# moondancer register map
Vendor: luna-soc
TODO device.description
Registers are 8-bit, read-write, reset 0x0 unless marked. A register's access mark holds for its fields unless they carry their own. Offsets are from the block's base; lines under a group give offsets from that group; [hi:lo] are bit positions; {n}, {i} and the like mark numbered series; 'fields as' and 'values as' point back to an identical list; <NAME> marks a mode.

## Memory map
0xF0000000 leds size 0x6
0xF0000100 gpio0 size 0x6
0xF0000200 gpio1 size 0x6
0xF0000300 uart0 size 0x14
0xF0000400 uart1 size 0x14
0xF0000500 timer0 size 0x12
0xF0000600 timer1 size 0x12
0xF0000700 spi0 size 0x10
0xF0000800 usb0 size 0xA
0xF0000900 usb0_ep_control size 0x12
0xF0000A00 usb0_ep_in size 0x12
0xF0000B00 usb0_ep_out size 0x22
0xF0000C00 usb1 size 0xA
0xF0000D00 usb1_ep_control size 0x12
0xF0000E00 usb1_ep_in size 0x12
0xF0000F00 usb1_ep_out size 0x22
0xF0001000 usb2 size 0xA
0xF0001100 usb2_ep_control size 0x12
0xF0001200 usb2_ep_in size 0x12
0xF0001300 usb2_ep_out size 0x22
0xF0001400 advertiser size 0x1
0xF0001500 info size 0x2
0xF0001600 user0 size 0x4

## Interrupts
0 timer0
1 timer1
2 usb0
3 usb0_ep_control
4 usb0_ep_in
5 usb0_ep_out
6 usb1
7 usb1_ep_control
8 usb1_ep_in
9 usb1_ep_out
10 usb2
11 usb2_ep_control
12 usb2_ep_in
13 usb2_ep_out

## leds
Base 0xF0000000
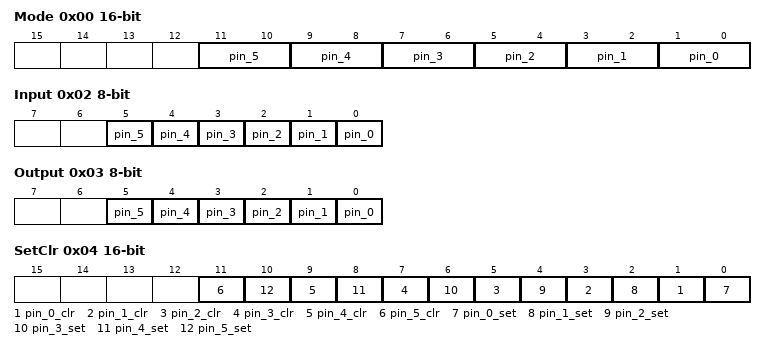
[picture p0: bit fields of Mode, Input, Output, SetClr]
0x00 Mode 16-bit — Mode register. This :class:`csr.Register` contains an array of ``pin_count`` read/write fields. Each field is 2-bit wide and its possible values are defined by the :class:`PinMode` enumeration. If ``pin_count`` is 8, then the register has the following fields: .. bitfield:: :bits: 16 [ { "name": "pin[0]", "bits": 2, "attr": "RW" }, { "name": "pin[1]", "bits": 2, "attr": "RW" }, { "name": "pin[2]", "bits": 2, "attr": "RW" }, { "name": "pin[3]", "bits": 2, "attr": "RW" }, { "name": "pin[4]", "bits": 2, "attr": "RW" }, { "name": "pin[5]", "bits": 2, "attr": "RW" }, { "name": "pin[6]", "bits": 2, "attr": "RW" }, { "name": "pin[7]", "bits": 2, "attr": "RW" }, ] Parameters ---------- pin_count : :class:`int` Number of GPIO pins.
  [2n+1:2n] pin_{n} (n=0..5)
0x02 Input — Input register. This :class:`csr.Register` contains an array of ``pin_count`` read-only fields. Each field is 1-bit wide and driven by the input of its associated pin in the :attr:`Peripheral.pins` array. Values sampled from pin inputs go through :attr:`Peripheral.input_stages` synchronization stages (on a rising edge of ``ClockSignal("sync")``) before reaching the register. If ``pin_count`` is 8, then the register has the following fields: .. bitfield:: :bits: 8 [ { "name": "pin[0]", "bits": 1, "attr": "R" }, { "name": "pin[1]", "bits": 1, "attr": "R" }, { "name": "pin[2]", "bits": 1, "attr": "R" }, { "name": "pin[3]", "bits": 1, "attr": "R" }, { "name": "pin[4]", "bits": 1, "attr": "R" }, { "name": "pin[5]", "bits": 1, "attr": "R" }, { "name": "pin[6]", "bits": 1, "attr": "R" }, { "name": "pin[7]", "bits": 1, "attr": "R" }, ] Parameters ---------- pin_count : :class:`int` Number of GPIO pins.
  [n] pin_{n} ro (n=0..5)
0x03 Output — Output register. This :class:`csr.Register` contains an array of ``pin_count`` read/write fields. Each field is 1-bit wide and drives the output of its associated pin in the :attr:`Peripheral.pins` array, depending on its associated :class:`~Peripheral.Mode` field. If ``pin_count`` is 8, then the register has the following fields: .. bitfield:: :bits: 8 [ { "name": "pin[0]", "bits": 1, "attr": "RW" }, { "name": "pin[1]", "bits": 1, "attr": "RW" }, { "name": "pin[2]", "bits": 1, "attr": "RW" }, { "name": "pin[3]", "bits": 1, "attr": "RW" }, { "name": "pin[4]", "bits": 1, "attr": "RW" }, { "name": "pin[5]", "bits": 1, "attr": "RW" }, { "name": "pin[6]", "bits": 1, "attr": "RW" }, { "name": "pin[7]", "bits": 1, "attr": "RW" }, ] Parameters ---------- pin_count : :class:`int` Number of GPIO pins.
  [n] pin_{n} (n=0..5)
0x04 SetClr 16-bit — Output set/clear register. This :class:`csr.Register` contains an array of ``pin_count`` write-only fields. Each field is 2-bit wide; writing it can modify its associated :class:`~Peripheral.Output` field as a side-effect. If ``pin_count`` is 8, then the register has the following fields: .. bitfield:: :bits: 16 [ { "name": "pin[0]", "bits": 2, "attr": "W" }, { "name": "pin[1]", "bits": 2, "attr": "W" }, { "name": "pin[2]", "bits": 2, "attr": "W" }, { "name": "pin[3]", "bits": 2, "attr": "W" }, { "name": "pin[4]", "bits": 2, "attr": "W" }, { "name": "pin[5]", "bits": 2, "attr": "W" }, { "name": "pin[6]", "bits": 2, "attr": "W" }, { "name": "pin[7]", "bits": 2, "attr": "W" }, ] - Writing `0b01` to a field sets its associated :class:`~Peripheral.Output` field. - Writing `0b10` to a field clears its associated :class:`~Peripheral.Output` field. - Writing `0b00` or `0b11` to a field has no side-effect. Parameters ---------- pin_count : :class:`int` Number of GPIO pins.
  [2n+1] pin_{n}_clr wo (n=0..5), [2n] pin_{n}_set wo (n=0..5)
